# core_cm4 register map
Registers are read-write, no defined reset value unless marked. A register's access mark holds for its fields unless they carry their own. Offsets are from the block's base; [hi:lo] are bit positions; {n}, {i} and the like mark numbered series.

## ITM — Instrumentation Trace Macrocell
Base 0xE0000000
{0x0+4i} PORT[{i}] (i=0..31) wo — ITM Stimulus Port Registers
0xE00 TER — ITM Trace Enable Register
0xE40 TPR — ITM Trace Privilege Register
  [4:0] PRIVMASK
0xE80 TCR — ITM Trace Control Register
  [24:23] BUSY
  [23:16] TraceBusID — ATBID
  [12:10] GTSFREQ — Global timestamp frequency
  [10:8] TSPrescale
  [5:4] SWOENA
  [4:3] DWTENA
  [3:2] SYNCENA
  [2:1] TSENA
  [1:0] ITMENA — ITM Enable bit
0xEF8 IWR wo — ITM Integration Write Register
  [1:0] ATVALIDM
0xEFC IRR ro — ITM Integration Read Register
  [1:0] ATREADYM
0xF00 IMCR — ITM Integration Mode Control Register
  [1:0] INTEGRATION
0xFB0 LAR wo — ITM Lock Access Register
0xFB4 LSR ro — ITM Lock Status Register
  [3:2] ByteAcc, [2:1] Access, [1:0] Present
{0xFC0+4i} PID{i} ro (i=4..7) — ITM Peripheral Identification Register #{i}
{0xFE0+4i} PID{i} ro (i=0..3) — ITM Peripheral Identification Register #{i}
{0xFF0+4i} CID{i} ro (i=0..3) — ITM Component Identification Register #{i}

## DWT — Data Watchpoint and Trace
Base 0xE0001000
0x00 CTRL — Control Register
  [32:28] NUMCOMP, [28:27] NOTRCPKT, [27:26] NOEXTTRIG, [26:25] NOCYCCNT, [25:24] NOPRFCNT, [23:22] CYCEVTENA, [22:21] FOLDEVTENA, [21:20] LSUEVTENA, [20:19] SLEEPEVTENA, [19:18] EXCEVTENA, [18:17] CPIEVTENA, [17:16] EXCTRCENA, [13:12] PCSAMPLENA, [12:10] SYNCTAP, [10:9] CYCTAP, [9:5] POSTINIT, [5:1] POSTPRESET, [1:0] CYCCNTENA
0x04 CYCCNT — Cycle Count Register
0x08 CPICNT — CPI Count Register
  [8:0] CPICNT
0x0C EXCCNT — Exception Overhead Count Register
  [8:0] EXCCNT
0x10 SLEEPCNT — Sleep Count Register
  [8:0] SLEEPCNT
0x14 LSUCNT — LSU Count Register
  [8:0] LSUCNT
0x18 FOLDCNT — Folded-instruction Count Register
  [8:0] FOLDCNT
0x1C PCSR ro — Program Counter Sample Register
{0x20+0x10*i} COMP{i} (i=0..3) — Comparator Register {i}
{0x24+0x10*i} MASK{i} (i=0..3) — Mask Register {i}
{0x28+0x10*i} FUNCTION{i} (i=0..3) — Function Register {i}

## TPI — Trace Port Interface
Base 0xE0040000
0x00 SSPSR — Supported Parallel Port Size Register
0x04 CSPSR — Current Parallel Port Size Register
0x10 ACPR — Asynchronous Clock Prescaler Register
  [13:0] PRESCALER
0xF0 SPPR — Selected Pin Protocol Register
  [2:0] TXMODE
0x300 FFSR ro — Formatter and Flush Status Register
  [4:3] FtNonStop, [3:2] TCPresent, [2:1] FtStopped, [1:0] FlInProg
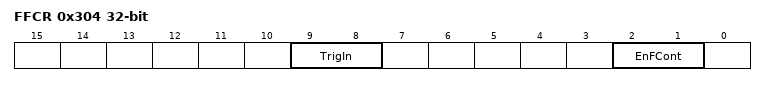
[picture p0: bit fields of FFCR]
0x304 FFCR — Formatter and Flush Control Register
  [9:8] TrigIn, [2:1] EnFCont
0x308 FSCR ro — Formatter Synchronization Counter Register
0xEE8 TRIGGER ro
  [1:0] TRIGGER
0xEEC FIFO0 ro — Integration ETM Data
  [31:29] ITM_ATVALID, [29:27] ITM_bytecount, [28:26] ETM_ATVALID, [26:24] ETM_bytecount, [24:16] ETM2, [16:8] ETM1, [8:0] ETM0
0xEF0 ITATBCTR2 ro
  [1:0] ATREADY
0xEF8 ITATBCTR0 ro
  [1:0] ATREADY
0xEFC FIFO1 ro — Integration ITM Data
  [31:29] ITM_ATVALID, [29:27] ITM_bytecount, [28:26] ETM_ATVALID, [26:24] ETM_bytecount, [24:16] ITM2, [16:8] ITM1, [8:0] ITM0
0xF00 ITCTRL — Integration Mode Control
  [1:0] Mode
0xFA0 CLAIMSET — Claim tag set
0xFA4 CLAIMCLR — Claim tag clear
0xFC8 DEVID ro — TPIU_DEVID
  [12:11] NRZVALID, [11:10] MANCVALID, [10:9] PTINVALID, [9:6] MinBufSz, [6:5] AsynClkIn, [5:0] NrTraceInput
0xFCC DEVTYPE ro — TPIU_DEVTYPE
  [8:4] MajorType, [4:0] SubType

## CoreDebug
Base 0xE000EDF0
0x00 DHCSR — Debug Halting Control and Status Register
  [26:25] S_RESET_ST, [25:24] S_RETIRE_ST, [20:19] S_LOCKUP, [19:18] S_SLEEP, [18:17] S_HALT, [32:16] DBGKEY, [17:16] S_REGRDY, [6:5] C_SNAPSTALL, [4:3] C_MASKINTS, [3:2] C_STEP, [2:1] C_HALT, [1:0] C_DEBUGEN
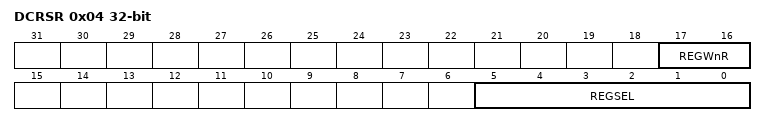
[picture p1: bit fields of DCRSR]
0x04 DCRSR wo — Debug Core Register Selector Register
  [17:16] REGWnR, [5:0] REGSEL
0x08 DCRDR — Debug Core Register Data Register
0x0C DEMCR — Debug Exception and Monitor Control Register
  [25:24] TRCENA, [20:19] MON_REQ, [19:18] MON_STEP, [18:17] MON_PEND, [17:16] MON_EN, [11:10] VC_HARDERR, [10:9] VC_INTERR, [9:8] VC_BUSERR, [8:7] VC_STATERR, [7:6] VC_CHKERR, [6:5] VC_NOCPERR, [5:4] VC_MMERR, [1:0] VC_CORERESET

## MPU — Memory Protection Unit
Base 0xE000ED90
0x00 TYPE ro — MPU Type Register
  [24:16] IREGION, [16:8] DREGION, [1:0] SEPARATE
0x04 CTRL — MPU Control Register
  [3:2] PRIVDEFENA, [2:1] HFNMIENA, [1:0] ENABLE
0x08 RNR — MPU Region RNRber Register
  [8:0] REGION
0x0C RBAR — MPU Region Base Address Register
  [32:5] ADDR, [5:4] VALID, [4:0] REGION
0x10 RASR — MPU Region Attribute and Size Register
  [29:28] XN — ATTRS.XN
  [27:24] AP — ATTRS.AP
  [22:19] TEX — ATTRS.TEX
  [19:18] S — ATTRS.S
  [18:17] C — ATTRS.C
  [32:16] ATTRS — MPU Region Attribute field
  [17:16] B — ATTRS.B
  [16:8] SRD — Sub-Region Disable
  [6:1] SIZE — Region Size Field
  [1:0] ENABLE — Region enable bit
{0xC+8i} RBAR_A{i} (i=1..3) — MPU Alias {i} Region Base Address Register
{0x10+8i} RASR_A{i} (i=1..3) — MPU Alias {i} Region Attribute and Size Register

## FPU — Floating Point Unit
Base 0xE000EF30
0x04 FPCCR — Floating-Point Context Control Register
  [32:31] ASPEN — ASPEN bit
  [31:30] LSPEN
  [9:8] MONRDY
  [7:6] BFRDY
  [6:5] MMRDY
  [5:4] HFRDY
  [4:3] THREAD — processor mode bit
  [2:1] USER — privilege level bit
  [1:0] LSPACT — Lazy state preservation active bit
0x08 FPCAR — Floating-Point Context Address Register
  [32:3] ADDRESS — ADDRESS bit
0x0C FPDSCR — Floating-Point Default Status Control Register
  [27:26] AHP — AHP bit
  [26:25] DN — DN bit
  [25:24] FZ — FZ bit
  [24:22] RMode — RMode bit
0x10 MVFR0 ro — Media and FP Feature Register 0
  [32:28] FP_rounding_modes — FP rounding modes bits
  [28:24] Short_vectors — Short vectors bits
  [24:20] Square_root — Square root bits
  [20:16] Divide — Divide bits
  [16:12] FP_excep_trapping — FP exception trapping bits
  [12:8] Double_precision — Double-precision bits
  [8:4] Single_precision — Single-precision bits
  [4:0] A_SIMD_registers — A_SIMD registers bits
0x14 MVFR1 ro — Media and FP Feature Register 1
  [32:28] FP_fused_MAC — FP fused MAC bits
  [28:24] FP_HPFP — FP HPFP bits
  [8:4] D_NaN_mode — D_NaN mode bits
  [4:0] FtZ_mode — FtZ mode bits
